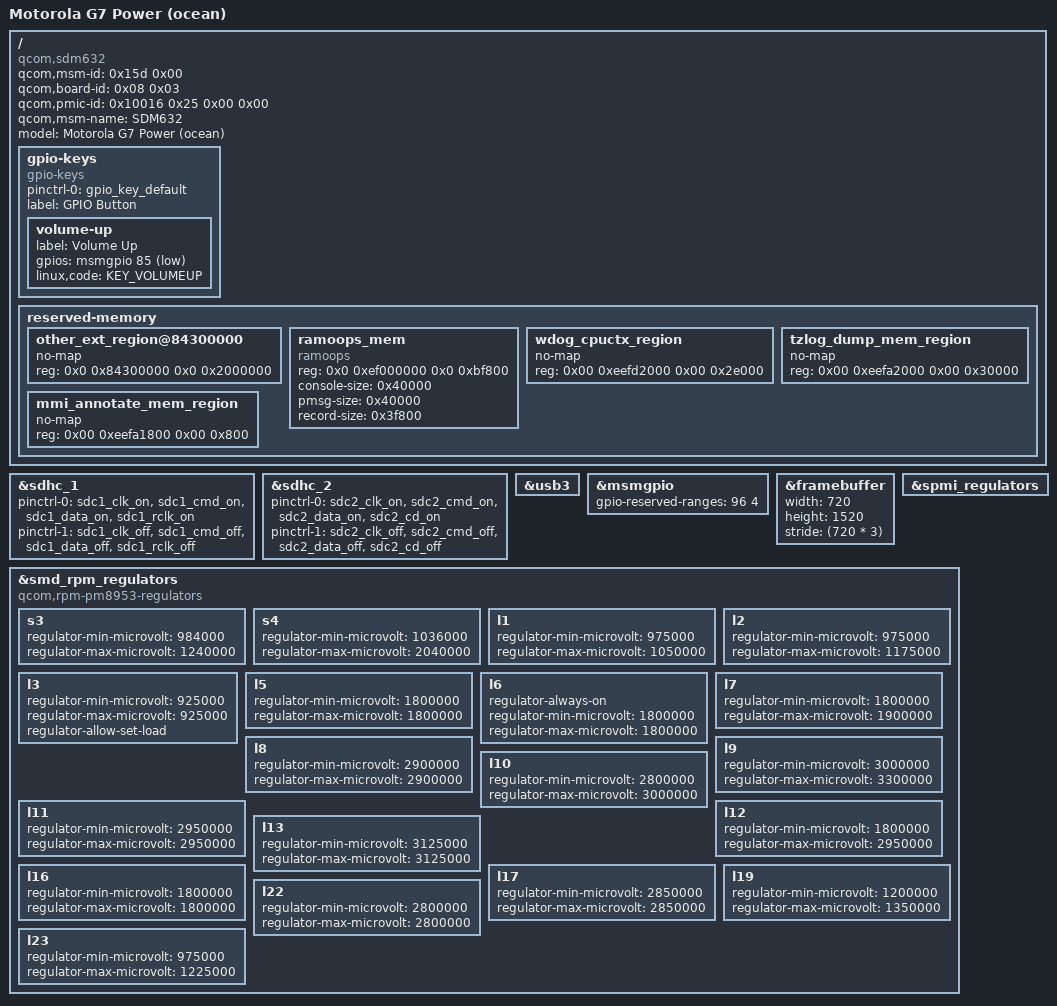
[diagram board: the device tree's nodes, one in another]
// SPDX-License-Identifier: GPL-2.0-only

/dts-v1/;

#include "sdm632.dtsi"
#include "pm8953.dtsi"
#include <dt-bindings/gpio/gpio.h>

/ {
	qcom,msm-id = <0x15d 0x00>;
	qcom,board-id = <0x08 0x03>;
	qcom,pmic-id = <0x10016 0x25 0x00 0x00>;
	qcom,msm-name = "SDM632";
	model = "Motorola G7 Power (ocean)";
	compatible = "qcom,sdm632", "qcom,msm8953";

	gpio-keys {
		compatible = "gpio-keys";

		pinctrl-names = "default";
		pinctrl-0 = <&gpio_key_default>;

		label = "GPIO Button";

		volume-up {
			label = "Volume Up";
			gpios = <&msmgpio 85 GPIO_ACTIVE_LOW>;
			linux,code = <KEY_VOLUMEUP>;
		};
	};

	reserved-memory {
		#address-cells = <2>;
		#size-cells = <2>;
		ranges;

		/delete-node/other_ext_region@85b00000;

		other_ext_region@84300000 {
			no-map;
			reg = <0x0 0x84300000 0x0 0x2000000>;
		};

		ramoops_mem {
			compatible = "ramoops";
			reg = <0x0 0xef000000 0x0 0xbf800>;
			console-size = <0x40000>;
			pmsg-size = <0x40000>;
			record-size = <0x3f800>;
		};

		wdog_cpuctx_region {
			no-map;
			reg = <0x00 0xeefd2000 0x00 0x2e000>;
		};

		tzlog_dump_mem_region {
			no-map;
			reg = <0x00 0xeefa2000 0x00 0x30000>;
		};

		mmi_annotate_mem_region {
			no-map;
			reg = <0x00 0xeefa1800 0x00 0x800>;
		};

	};
};

&sdhc_1 {
	status = "okay";
	pinctrl-names = "default", "sleep";
	pinctrl-0 = <&sdc1_clk_on &sdc1_cmd_on &sdc1_data_on  &sdc1_rclk_on>;
	pinctrl-1 = <&sdc1_clk_off &sdc1_cmd_off &sdc1_data_off &sdc1_rclk_off>;
};

&sdhc_2 {
	status = "okay";
	// cd-gpios = <&msmgpio 133 GPIO_ACTIVE_HIGH>;
	/* TODO: test this */
	pinctrl-names = "default", "sleep";
	pinctrl-0 = <&sdc2_clk_on &sdc2_cmd_on &sdc2_data_on &sdc2_cd_on>;
	pinctrl-1 = <&sdc2_clk_off &sdc2_cmd_off &sdc2_data_off &sdc2_cd_off>;
};

&usb3 {
	status = "okay";
};

&msmgpio {
	gpio-reserved-ranges = <96 4>;
};

&framebuffer {
	status = "okay";

	width = <720>;
	height = <1520>;
	stride = <(720 * 3)>;
};

&spmi_regulators {
	status = "okay";
};

&smd_rpm_regulators {
	compatible = "qcom,rpm-pm8953-regulators";

#if 0
	s1_level { // Modem
		status = "okay";
		regulator-min-microvolt = <0x10>;
		regulator-max-microvolt = <0x180>;
	};
#endif
	s3 { // CSI
		status = "okay";
		regulator-min-microvolt = <984000>;
		regulator-max-microvolt = <1240000>;
	};
	s4 { // Audio codec
		status = "okay";
		regulator-min-microvolt = <1036000>;
		regulator-max-microvolt = <2040000>;
	};
	l1 { // unused
		status = "okay";
		regulator-min-microvolt = <975000>;
		regulator-max-microvolt = <1050000>;
	};
	l2 { // Always-on
		status = "okay";
		regulator-min-microvolt = <975000>;
		regulator-max-microvolt = <1175000>;
	};
	l3 { // Usb, mdss phy
		status = "okay";
		regulator-min-microvolt = <925000>;
		regulator-max-microvolt = <925000>;
		regulator-allow-set-load;
	};
	l5 { // wcnss, sdhci, codec
		status = "okay";
		regulator-min-microvolt = <1800000>;
		regulator-max-microvolt = <1800000>;
	};
	l6 { // DSI
		status = "okay";
		regulator-always-on;
		regulator-min-microvolt = <1800000>;
		regulator-max-microvolt = <1800000>;
		};
	l7 {
		status = "okay";
		regulator-min-microvolt = <1800000>;
		regulator-max-microvolt = <1900000>;
	};
	l8 { // sdhci
		status = "okay";
		regulator-min-microvolt = <2900000>;
		regulator-max-microvolt = <2900000>;
	};
	l9 { // wcnss
		status = "okay";
		regulator-min-microvolt = <3000000>;
		regulator-max-microvolt = <3300000>;
	};
	l10 { // unused
		status = "okay";
		regulator-min-microvolt = <2800000>;
		regulator-max-microvolt = <3000000>;
	};
	l11 { // sdhci
		status = "okay";
		regulator-min-microvolt = <2950000>;
		regulator-max-microvolt = <2950000>;
	};
	l12 { // sdhci
		status = "okay";
		regulator-min-microvolt = <1800000>;
		regulator-max-microvolt = <2950000>;
	};
	l13 { // audio codec, usb phy
		status = "okay";
		regulator-min-microvolt = <3125000>;
		regulator-max-microvolt = <3125000>;
	};
	l16 { // unused
		status = "okay";
		regulator-min-microvolt = <1800000>;
		regulator-max-microvolt = <1800000>;
	};
	l17 { // dsi
		status = "okay";
		regulator-min-microvolt = <2850000>;
		regulator-max-microvolt = <2850000>;
	};
	l19 { // wcnss
		status = "okay";
		regulator-min-microvolt = <1200000>;
		regulator-max-microvolt = <1350000>;
	};
	l22 { // dsi
		status = "okay";
		regulator-min-microvolt = <2800000>;
		regulator-max-microvolt = <2800000>;
	};
	l23 { // camera
		status = "okay";
		regulator-min-microvolt = <975000>;
		regulator-max-microvolt = <1225000>;
	};
};
